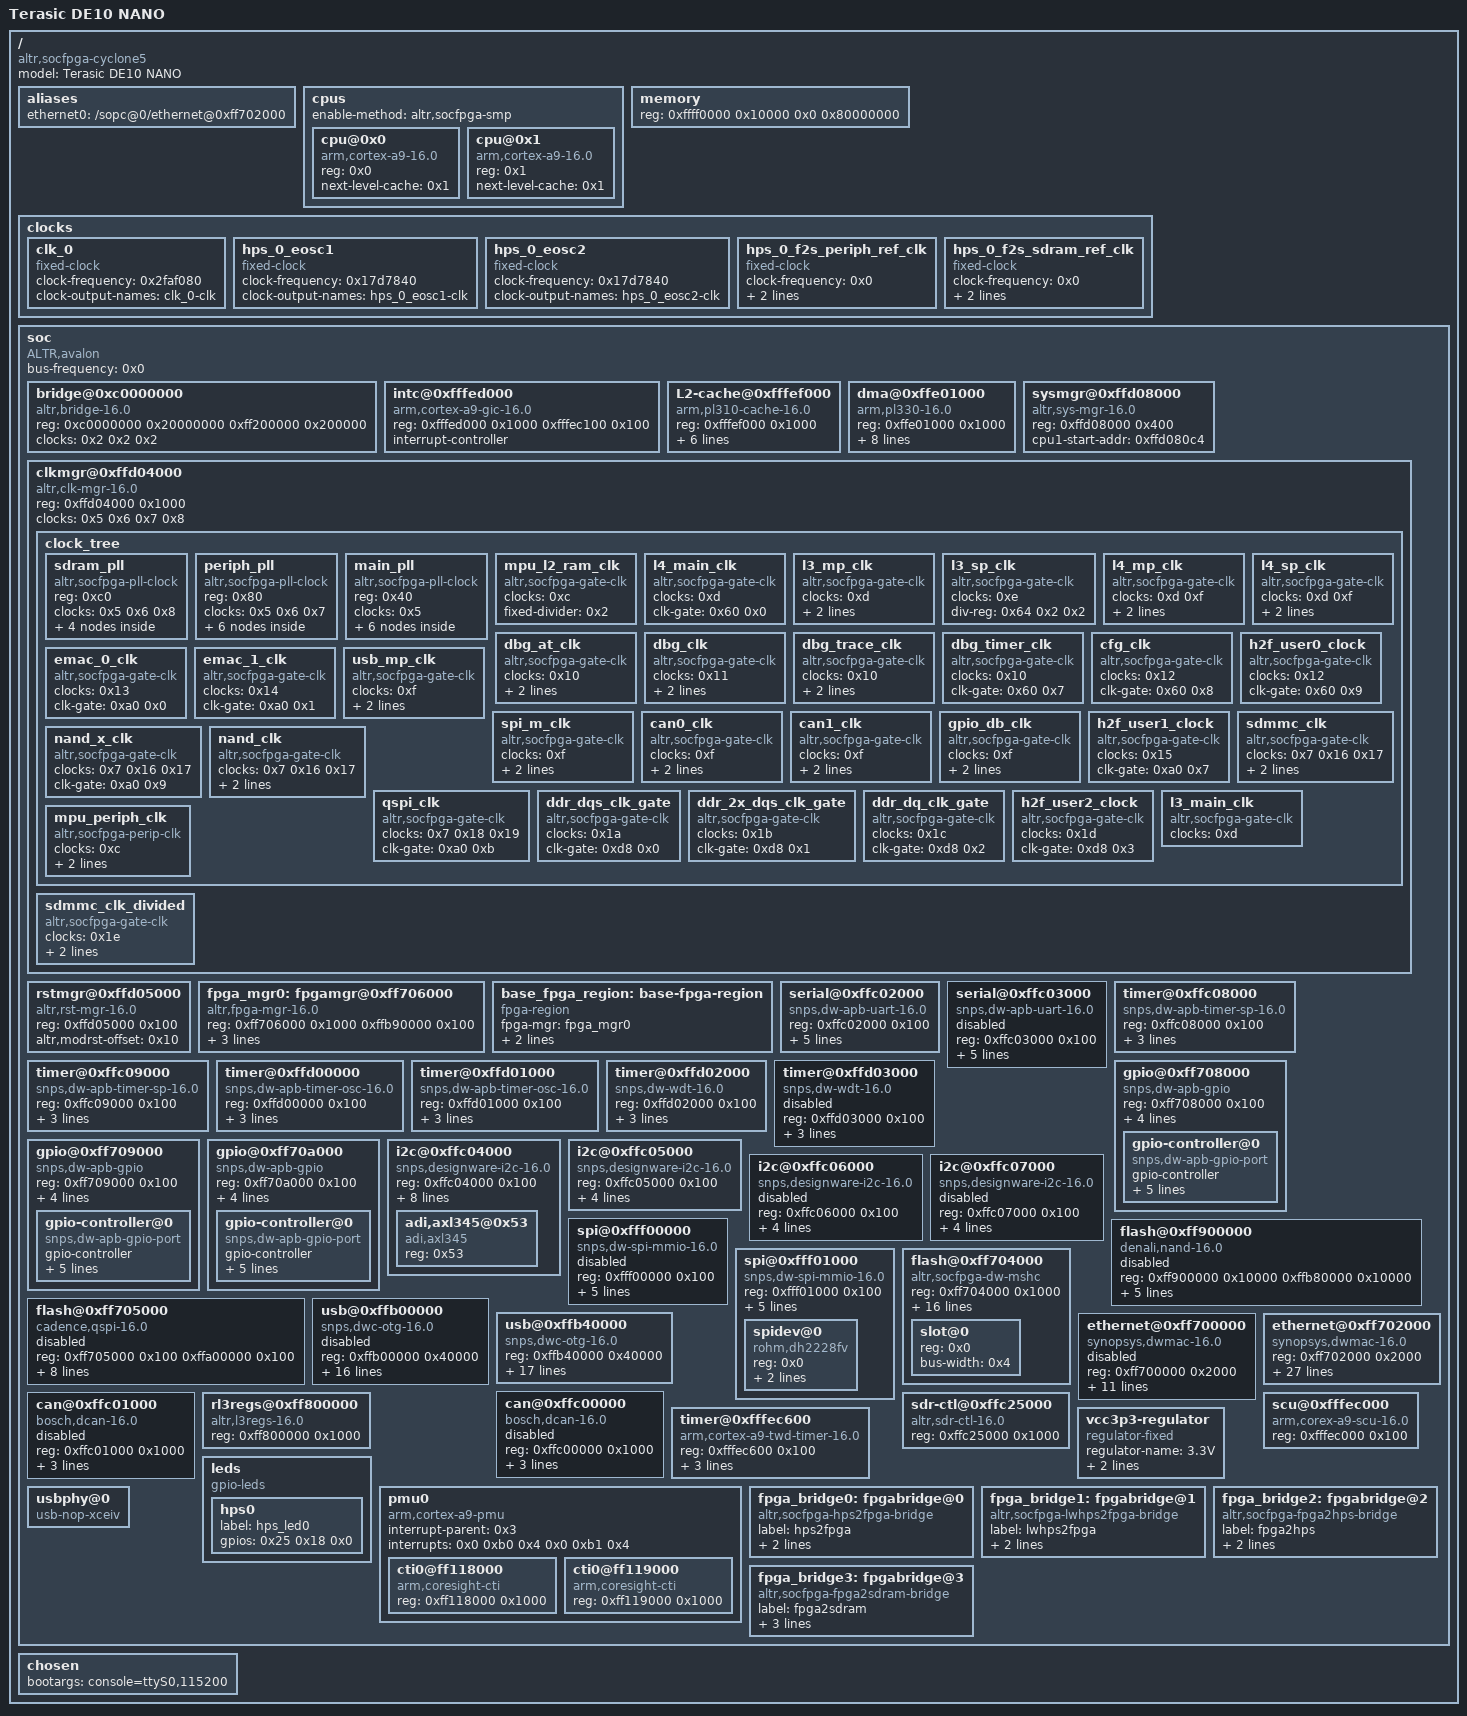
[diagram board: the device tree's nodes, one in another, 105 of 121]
/dts-v1/;

/ {
	model = "Terasic DE10 NANO";
	compatible = "altr,socfpga-cyclone5", "altr,socfpga";
	#address-cells = <0x1>;
	#size-cells = <0x1>;

	aliases {
		ethernet0 = "/sopc@0/ethernet@0xff702000";
	};

	cpus {
		#address-cells = <0x1>;
		#size-cells = <0x0>;
		enable-method = "altr,socfpga-smp";

		cpu@0x0 {
			device_type = "cpu";
			compatible = "arm,cortex-a9-16.0", "arm,cortex-a9";
			reg = <0x0>;
			next-level-cache = <0x1>;
		};

		cpu@0x1 {
			device_type = "cpu";
			compatible = "arm,cortex-a9-16.0", "arm,cortex-a9";
			reg = <0x1>;
			next-level-cache = <0x1>;
		};
	};

	memory {
		device_type = "memory";
		reg = <0xffff0000 0x10000 0x0 0x80000000>;
	};

	clocks {
		#address-cells = <0x1>;
		#size-cells = <0x1>;

		clk_0 {
			compatible = "fixed-clock";
			#clock-cells = <0x0>;
			clock-frequency = <0x2faf080>;
			clock-output-names = "clk_0-clk";
			linux,phandle = <0x2>;
			phandle = <0x2>;
		};

		hps_0_eosc1 {
			compatible = "fixed-clock";
			#clock-cells = <0x0>;
			clock-frequency = <0x17d7840>;
			clock-output-names = "hps_0_eosc1-clk";
			linux,phandle = <0x5>;
			phandle = <0x5>;
		};

		hps_0_eosc2 {
			compatible = "fixed-clock";
			#clock-cells = <0x0>;
			clock-frequency = <0x17d7840>;
			clock-output-names = "hps_0_eosc2-clk";
			linux,phandle = <0x6>;
			phandle = <0x6>;
		};

		hps_0_f2s_periph_ref_clk {
			compatible = "fixed-clock";
			#clock-cells = <0x0>;
			clock-frequency = <0x0>;
			clock-output-names = "hps_0_f2s_periph_ref_clk-clk";
			linux,phandle = <0x7>;
			phandle = <0x7>;
		};

		hps_0_f2s_sdram_ref_clk {
			compatible = "fixed-clock";
			#clock-cells = <0x0>;
			clock-frequency = <0x0>;
			clock-output-names = "hps_0_f2s_sdram_ref_clk-clk";
			linux,phandle = <0x8>;
			phandle = <0x8>;
		};
	};

	soc {
		device_type = "soc";
		ranges;
		#address-cells = <0x1>;
		#size-cells = <0x1>;
		compatible = "ALTR,avalon", "simple-bus";
		bus-frequency = <0x0>;

		bridge@0xc0000000 {
			compatible = "altr,bridge-16.0", "simple-bus";
			reg = <0xc0000000 0x20000000 0xff200000 0x200000>;
			reg-names = "axi_h2f", "axi_h2f_lw";
			clocks = <0x2 0x2 0x2>;
			clock-names = "h2f_axi_clock", "h2f_lw_axi_clock", "f2h_sdram0_clock";
			#address-cells = <0x2>;
			#size-cells = <0x1>;
		};

		intc@0xfffed000 {
			compatible = "arm,cortex-a9-gic-16.0", "arm,cortex-a9-gic";
			reg = <0xfffed000 0x1000 0xfffec100 0x100>;
			reg-names = "axi_slave0", "axi_slave1";
			interrupt-controller;
			#interrupt-cells = <0x3>;
			linux,phandle = <0x3>;
			phandle = <0x3>;
		};

		L2-cache@0xfffef000 {
			compatible = "arm,pl310-cache-16.0", "arm,pl310-cache";
			reg = <0xfffef000 0x1000>;
			interrupt-parent = <0x3>;
			interrupts = <0x0 0x26 0x4>;
			cache-level = <0x2>;
			cache-unified;
			arm,tag-latency = <0x1 0x1 0x1>;
			arm,data-latency = <0x2 0x1 0x1>;
			linux,phandle = <0x1>;
			phandle = <0x1>;
		};

		dma@0xffe01000 {
			compatible = "arm,pl330-16.0", "arm,pl330", "arm,primecell";
			reg = <0xffe01000 0x1000>;
			interrupt-parent = <0x3>;
			interrupts = <0x0 0x68 0x4>;
			clocks = <0x4>;
			#dma-cells = <0x1>;
			#dma-channels = <0x8>;
			#dma-requests = <0x20>;
			clock-names = "apb_pclk";
			copy-align = <0x3>;
			nr-irqs = <0x9>;
			nr-valid-peri = <0x9>;
		};

		sysmgr@0xffd08000 {
			compatible = "altr,sys-mgr-16.0", "altr,sys-mgr", "syscon";
			reg = <0xffd08000 0x400>;
			cpu1-start-addr = <0xffd080c4>;
			linux,phandle = <0x2a>;
			phandle = <0x2a>;
		};

		clkmgr@0xffd04000 {
			compatible = "altr,clk-mgr-16.0", "altr,clk-mgr";
			reg = <0xffd04000 0x1000>;
			clocks = <0x5 0x6 0x7 0x8>;
			clock-names = "eosc1", "eosc2", "f2s_periph_ref_clk", "f2s_sdram_ref_clk";

			clock_tree {
				#size-cells = <0x0>;
				#address-cells = <0x1>;

				sdram_pll {
					compatible = "altr,socfpga-pll-clock";
					reg = <0xc0>;
					clocks = <0x5 0x6 0x8>;
					clock-names = "hps_0_eosc1", "hps_0_eosc2", "hps_0_f2s_sdram_ref_clk";
					#clock-cells = <0x0>;
					#address-cells = <0x1>;
					#size-cells = <0x0>;
					linux,phandle = <0x9>;
					phandle = <0x9>;

					ddr_dqs_clk {
						compatible = "altr,socfpga-perip-clk";
						reg = <0xc8>;
						clocks = <0x9>;
						#clock-cells = <0x0>;
						linux,phandle = <0x1a>;
						phandle = <0x1a>;
					};

					ddr_2x_dqs_clk {
						compatible = "altr,socfpga-perip-clk";
						reg = <0xcc>;
						clocks = <0x9>;
						#clock-cells = <0x0>;
						linux,phandle = <0x1b>;
						phandle = <0x1b>;
					};

					ddr_dq_clk {
						compatible = "altr,socfpga-perip-clk";
						reg = <0xd0>;
						clocks = <0x9>;
						#clock-cells = <0x0>;
						linux,phandle = <0x1c>;
						phandle = <0x1c>;
					};

					s2f_usr2_clk {
						compatible = "altr,socfpga-perip-clk";
						reg = <0xd4>;
						clocks = <0x9>;
						#clock-cells = <0x0>;
						linux,phandle = <0x1d>;
						phandle = <0x1d>;
					};
				};

				periph_pll {
					compatible = "altr,socfpga-pll-clock";
					reg = <0x80>;
					clocks = <0x5 0x6 0x7>;
					clock-names = "hps_0_eosc1", "hps_0_eosc2", "hps_0_f2s_periph_ref_clk";
					#clock-cells = <0x0>;
					#address-cells = <0x1>;
					#size-cells = <0x0>;
					linux,phandle = <0xa>;
					phandle = <0xa>;

					per_nand_mmc_clk {
						compatible = "altr,socfpga-perip-clk";
						reg = <0x94>;
						clocks = <0xa>;
						#clock-cells = <0x0>;
						linux,phandle = <0x17>;
						phandle = <0x17>;
					};

					per_base_clk {
						compatible = "altr,socfpga-perip-clk";
						reg = <0x98>;
						clocks = <0xa>;
						#clock-cells = <0x0>;
						linux,phandle = <0xf>;
						phandle = <0xf>;
					};

					per_qspi_clk {
						compatible = "altr,socfpga-perip-clk";
						reg = <0x90>;
						clocks = <0xa>;
						#clock-cells = <0x0>;
						linux,phandle = <0x19>;
						phandle = <0x19>;
					};

					s2f_usr1_clk {
						compatible = "altr,socfpga-perip-clk";
						reg = <0x9c>;
						clocks = <0xa>;
						#clock-cells = <0x0>;
						linux,phandle = <0x15>;
						phandle = <0x15>;
					};

					emac0_clk {
						compatible = "altr,socfpga-perip-clk";
						reg = <0x88>;
						clocks = <0xa>;
						#clock-cells = <0x0>;
						linux,phandle = <0x13>;
						phandle = <0x13>;
					};

					emac1_clk {
						compatible = "altr,socfpga-perip-clk";
						reg = <0x8c>;
						clocks = <0xa>;
						#clock-cells = <0x0>;
						linux,phandle = <0x14>;
						phandle = <0x14>;
					};
				};

				main_pll {
					compatible = "altr,socfpga-pll-clock";
					reg = <0x40>;
					clocks = <0x5>;
					#clock-cells = <0x0>;
					#address-cells = <0x1>;
					#size-cells = <0x0>;
					linux,phandle = <0xb>;
					phandle = <0xb>;

					cfg_s2f_usr0_clk {
						compatible = "altr,socfpga-perip-clk";
						reg = <0x5c>;
						clocks = <0xb>;
						#clock-cells = <0x0>;
						linux,phandle = <0x12>;
						phandle = <0x12>;
					};

					main_qspi_clk {
						compatible = "altr,socfpga-perip-clk";
						reg = <0x54>;
						clocks = <0xb>;
						#clock-cells = <0x0>;
						linux,phandle = <0x18>;
						phandle = <0x18>;
					};

					dbg_base_clk {
						compatible = "altr,socfpga-perip-clk";
						reg = <0x50>;
						clocks = <0xb 0x5>;
						clock-names = "main_pll", "hps_0_eosc1";
						#clock-cells = <0x0>;
						div-reg = <0xe8 0x0 0x9>;
						linux,phandle = <0x10>;
						phandle = <0x10>;
					};

					mpuclk {
						compatible = "altr,socfpga-perip-clk";
						reg = <0x48>;
						clocks = <0xb>;
						#clock-cells = <0x0>;
						div-reg = <0xe0 0x0 0x9>;
						linux,phandle = <0xc>;
						phandle = <0xc>;
					};

					mainclk {
						compatible = "altr,socfpga-perip-clk";
						reg = <0x4c>;
						clocks = <0xb>;
						#clock-cells = <0x0>;
						div-reg = <0xe4 0x0 0x9>;
						linux,phandle = <0xd>;
						phandle = <0xd>;
					};

					main_nand_sdmmc_clk {
						compatible = "altr,socfpga-perip-clk";
						reg = <0x58>;
						clocks = <0xb>;
						#clock-cells = <0x0>;
						linux,phandle = <0x16>;
						phandle = <0x16>;
					};
				};

				mpu_l2_ram_clk {
					compatible = "altr,socfpga-gate-clk";
					clocks = <0xc>;
					#clock-cells = <0x0>;
					fixed-divider = <0x2>;
				};

				l4_main_clk {
					compatible = "altr,socfpga-gate-clk";
					clocks = <0xd>;
					#clock-cells = <0x0>;
					clk-gate = <0x60 0x0>;
					linux,phandle = <0x4>;
					phandle = <0x4>;
				};

				l3_mp_clk {
					compatible = "altr,socfpga-gate-clk";
					clocks = <0xd>;
					#clock-cells = <0x0>;
					clk-gate = <0x60 0x1>;
					div-reg = <0x64 0x0 0x2>;
					linux,phandle = <0xe>;
					phandle = <0xe>;
				};

				l3_sp_clk {
					compatible = "altr,socfpga-gate-clk";
					clocks = <0xe>;
					#clock-cells = <0x0>;
					div-reg = <0x64 0x2 0x2>;
				};

				l4_mp_clk {
					compatible = "altr,socfpga-gate-clk";
					clocks = <0xd 0xf>;
					clock-names = "mainclk", "per_base_clk";
					#clock-cells = <0x0>;
					clk-gate = <0x60 0x2>;
					div-reg = <0x64 0x4 0x3>;
					linux,phandle = <0x20>;
					phandle = <0x20>;
				};

				l4_sp_clk {
					compatible = "altr,socfpga-gate-clk";
					clocks = <0xd 0xf>;
					clock-names = "mainclk", "per_base_clk";
					#clock-cells = <0x0>;
					clk-gate = <0x60 0x3>;
					div-reg = <0x64 0x7 0x3>;
					linux,phandle = <0x1f>;
					phandle = <0x1f>;
				};

				dbg_at_clk {
					compatible = "altr,socfpga-gate-clk";
					clocks = <0x10>;
					#clock-cells = <0x0>;
					clk-gate = <0x60 0x4>;
					div-reg = <0x68 0x0 0x2>;
					linux,phandle = <0x11>;
					phandle = <0x11>;
				};

				dbg_clk {
					compatible = "altr,socfpga-gate-clk";
					clocks = <0x11>;
					#clock-cells = <0x0>;
					clk-gate = <0x60 0x5>;
					div-reg = <0x68 0x2 0x2>;
				};

				dbg_trace_clk {
					compatible = "altr,socfpga-gate-clk";
					clocks = <0x10>;
					#clock-cells = <0x0>;
					clk-gate = <0x60 0x6>;
					div-reg = <0x6c 0x0 0x3>;
				};

				dbg_timer_clk {
					compatible = "altr,socfpga-gate-clk";
					clocks = <0x10>;
					#clock-cells = <0x0>;
					clk-gate = <0x60 0x7>;
				};

				cfg_clk {
					compatible = "altr,socfpga-gate-clk";
					clocks = <0x12>;
					#clock-cells = <0x0>;
					clk-gate = <0x60 0x8>;
				};

				h2f_user0_clock {
					compatible = "altr,socfpga-gate-clk";
					clocks = <0x12>;
					#clock-cells = <0x0>;
					clk-gate = <0x60 0x9>;
				};

				emac_0_clk {
					compatible = "altr,socfpga-gate-clk";
					clocks = <0x13>;
					#clock-cells = <0x0>;
					clk-gate = <0xa0 0x0>;
				};

				emac_1_clk {
					compatible = "altr,socfpga-gate-clk";
					clocks = <0x14>;
					#clock-cells = <0x0>;
					clk-gate = <0xa0 0x1>;
				};

				usb_mp_clk {
					compatible = "altr,socfpga-gate-clk";
					clocks = <0xf>;
					#clock-cells = <0x0>;
					clk-gate = <0xa0 0x2>;
					div-reg = <0xa4 0x0 0x3>;
					linux,phandle = <0x27>;
					phandle = <0x27>;
				};

				spi_m_clk {
					compatible = "altr,socfpga-gate-clk";
					clocks = <0xf>;
					#clock-cells = <0x0>;
					clk-gate = <0xa0 0x3>;
					div-reg = <0xa4 0x3 0x3>;
					linux,phandle = <0x22>;
					phandle = <0x22>;
				};

				can0_clk {
					compatible = "altr,socfpga-gate-clk";
					clocks = <0xf>;
					#clock-cells = <0x0>;
					clk-gate = <0xa0 0x4>;
					div-reg = <0xa4 0x6 0x3>;
					linux,phandle = <0x2b>;
					phandle = <0x2b>;
				};

				can1_clk {
					compatible = "altr,socfpga-gate-clk";
					clocks = <0xf>;
					#clock-cells = <0x0>;
					clk-gate = <0xa0 0x5>;
					div-reg = <0xa4 0x9 0x3>;
					linux,phandle = <0x2c>;
					phandle = <0x2c>;
				};

				gpio_db_clk {
					compatible = "altr,socfpga-gate-clk";
					clocks = <0xf>;
					#clock-cells = <0x0>;
					clk-gate = <0xa0 0x6>;
					div-reg = <0xa8 0x0 0x18>;
				};

				h2f_user1_clock {
					compatible = "altr,socfpga-gate-clk";
					clocks = <0x15>;
					#clock-cells = <0x0>;
					clk-gate = <0xa0 0x7>;
				};

				sdmmc_clk {
					compatible = "altr,socfpga-gate-clk";
					clocks = <0x7 0x16 0x17>;
					clock-names = "hps_0_f2s_periph_ref_clk", "main_nand_sdmmc_clk", "per_nand_mmc_clk";
					#clock-cells = <0x0>;
					clk-gate = <0xa0 0x8>;
					clk-phase = <0x0 0x87>;
					linux,phandle = <0x1e>;
					phandle = <0x1e>;
				};

				nand_x_clk {
					compatible = "altr,socfpga-gate-clk";
					clocks = <0x7 0x16 0x17>;
					clock-names = "hps_0_f2s_periph_ref_clk", "main_nand_sdmmc_clk", "per_nand_mmc_clk";
					#clock-cells = <0x0>;
					clk-gate = <0xa0 0x9>;
				};

				nand_clk {
					compatible = "altr,socfpga-gate-clk";
					clocks = <0x7 0x16 0x17>;
					clock-names = "hps_0_f2s_periph_ref_clk", "main_nand_sdmmc_clk", "per_nand_mmc_clk";
					#clock-cells = <0x0>;
					clk-gate = <0xa0 0xa>;
					fixed-divider = <0x4>;
					linux,phandle = <0x21>;
					phandle = <0x21>;
				};

				qspi_clk {
					compatible = "altr,socfpga-gate-clk";
					clocks = <0x7 0x18 0x19>;
					clock-names = "hps_0_f2s_periph_ref_clk", "main_qspi_clk", "per_qspi_clk";
					#clock-cells = <0x0>;
					clk-gate = <0xa0 0xb>;
					linux,phandle = <0x23>;
					phandle = <0x23>;
				};

				ddr_dqs_clk_gate {
					compatible = "altr,socfpga-gate-clk";
					clocks = <0x1a>;
					#clock-cells = <0x0>;
					clk-gate = <0xd8 0x0>;
				};

				ddr_2x_dqs_clk_gate {
					compatible = "altr,socfpga-gate-clk";
					clocks = <0x1b>;
					#clock-cells = <0x0>;
					clk-gate = <0xd8 0x1>;
				};

				ddr_dq_clk_gate {
					compatible = "altr,socfpga-gate-clk";
					clocks = <0x1c>;
					#clock-cells = <0x0>;
					clk-gate = <0xd8 0x2>;
				};

				h2f_user2_clock {
					compatible = "altr,socfpga-gate-clk";
					clocks = <0x1d>;
					#clock-cells = <0x0>;
					clk-gate = <0xd8 0x3>;
				};

				l3_main_clk {
					compatible = "altr,socfpga-gate-clk";
					clocks = <0xd>;
					#clock-cells = <0x0>;
				};

				mpu_periph_clk {
					compatible = "altr,socfpga-perip-clk";
					clocks = <0xc>;
					#clock-cells = <0x0>;
					reg = <0x0>;
					fixed-divider = <0x4>;
					linux,phandle = <0x2d>;
					phandle = <0x2d>;
				};
			};

			sdmmc_clk_divided {
				#clock-cells = <0x0>;
				compatible = "altr,socfpga-gate-clk";
				clocks = <0x1e>;
				clk-gate = <0xa0 0x8>;
				fixed-divider = <0x4>;
				linux,phandle = <0x24>;
				phandle = <0x24>;
			};
		};

		rstmgr@0xffd05000 {
			compatible = "altr,rst-mgr-16.0", "altr,rst-mgr", "syscon";
			reg = <0xffd05000 0x100>;
			#reset-cells = <0x1>;
			altr,modrst-offset = <0x10>;
			linux,phandle = <0x29>;
			phandle = <0x29>;
		};

		fpga_mgr0: fpgamgr@0xff706000 {
			compatible = "altr,fpga-mgr-16.0", "altr,fpga-mgr";
			reg = <0xff706000 0x1000 0xffb90000 0x100>;
			reg-names = "axi_slave0", "axi_slave1";
			interrupt-parent = <0x3>;
			interrupts = <0x0 0xaf 0x4>;
			transport = "mmio";
		};

    base_fpga_region: base-fpga-region {
      compatible = "fpga-region";
      fpga-mgr = <&fpga_mgr0>;
      fpga-bridges = <&fpga_bridge0>, <&fpga_bridge1>,
                     <&fpga_bridge2>, <&fpga_bridge3>;

      #address-cells = <0x2>;
      #size-cells = <0x1>;
      ranges = <0x00000000 0x00000000 0xc0000000 0x20000000>,
               <0x00000001 0x00000000 0xff200000 0x00200000>;
    };
    
		serial@0xffc02000 {
			compatible = "snps,dw-apb-uart-16.0", "snps,dw-apb-uart";
			reg = <0xffc02000 0x100>;
			interrupt-parent = <0x3>;
			interrupts = <0x0 0xa2 0x4>;
			clocks = <0x1f>;
			reg-io-width = <0x4>;
			reg-shift = <0x2>;
			status = "okay";
		};

		serial@0xffc03000 {
			compatible = "snps,dw-apb-uart-16.0", "snps,dw-apb-uart";
			reg = <0xffc03000 0x100>;
			interrupt-parent = <0x3>;
			interrupts = <0x0 0xa3 0x4>;
			clocks = <0x1f>;
			reg-io-width = <0x4>;
			reg-shift = <0x2>;
			status = "disabled";
		};

		timer@0xffc08000 {
			compatible = "snps,dw-apb-timer-sp-16.0", "snps,dw-apb-timer-sp";
			reg = <0xffc08000 0x100>;
			interrupt-parent = <0x3>;
			interrupts = <0x0 0xa7 0x4>;
			clocks = <0x1f>;
			clock-names = "timer";
		};

		timer@0xffc09000 {
			compatible = "snps,dw-apb-timer-sp-16.0", "snps,dw-apb-timer-sp";
			reg = <0xffc09000 0x100>;
			interrupt-parent = <0x3>;
			interrupts = <0x0 0xa8 0x4>;
			clocks = <0x1f>;
			clock-names = "timer";
		};

		timer@0xffd00000 {
			compatible = "snps,dw-apb-timer-osc-16.0", "snps,dw-apb-timer-osc";
			reg = <0xffd00000 0x100>;
			interrupt-parent = <0x3>;
			interrupts = <0x0 0xa9 0x4>;
			clocks = <0x5>;
			clock-names = "timer";
		};

		timer@0xffd01000 {
			compatible = "snps,dw-apb-timer-osc-16.0", "snps,dw-apb-timer-osc";
			reg = <0xffd01000 0x100>;
			interrupt-parent = <0x3>;
			interrupts = <0x0 0xaa 0x4>;
			clocks = <0x5>;
			clock-names = "timer";
		};

		timer@0xffd02000 {
			compatible = "snps,dw-wdt-16.0", "snps,dw-wdt";
			reg = <0xffd02000 0x100>;
			interrupt-parent = <0x3>;
			interrupts = <0x0 0xab 0x4>;
			clocks = <0x5>;
			clock-names = "timer";
		};

		timer@0xffd03000 {
			compatible = "snps,dw-wdt-16.0", "snps,dw-wdt";
			reg = <0xffd03000 0x100>;
			interrupt-parent = <0x3>;
			interrupts = <0x0 0xac 0x4>;
			clocks = <0xf>;
			clock-names = "timer";
			status = "disabled";
		};

		gpio@0xff708000 {
			compatible = "snps,dw-apb-gpio", "snps,dw-gpio-16.0", "snps,dw-gpio";
			reg = <0xff708000 0x100>;
			interrupt-parent = <0x3>;
			interrupts = <0x0 0xa4 0x4>;
			clocks = <0x20>;
			#gpio-cells = <0x2>;
			gpio-controller;
			#address-cells = <0x1>;
			#size-cells = <0x0>;

			gpio-controller@0 {
				compatible = "snps,dw-apb-gpio-port";
				gpio-controller;
				#gpio-cells = <0x2>;
				snps,nr-gpios = <0x1d>;
				reg = <0x0>;
				interrupt-controller;
				#interrupt-cells = <0x2>;
				interrupts = <0x0 0xa4 0x4>;
				interrupt-parent = <0x3>;
			};
		};

		gpio@0xff709000 {
			compatible = "snps,dw-apb-gpio", "snps,dw-gpio-16.0", "snps,dw-gpio";
			reg = <0xff709000 0x100>;
			interrupt-parent = <0x3>;
			interrupts = <0x0 0xa5 0x4>;
			clocks = <0x20>;
			#gpio-cells = <0x2>;
			gpio-controller;
			#address-cells = <0x1>;
			#size-cells = <0x0>;

			gpio-controller@0 {
				compatible = "snps,dw-apb-gpio-port";
				gpio-controller;
				#gpio-cells = <0x2>;
				snps,nr-gpios = <0x1d>;
				reg = <0x0>;
				interrupt-controller;
				#interrupt-cells = <0x2>;
				interrupts = <0x0 0xa5 0x4>;
				interrupt-parent = <0x3>;
				linux,phandle = <0x25>;
				phandle = <0x25>;
			};
		};

		gpio@0xff70a000 {
			compatible = "snps,dw-apb-gpio", "snps,dw-gpio-16.0", "snps,dw-gpio";
			reg = <0xff70a000 0x100>;
			interrupt-parent = <0x3>;
			interrupts = <0x0 0xa6 0x4>;
			clocks = <0x20>;
			#gpio-cells = <0x2>;
			gpio-controller;
			#address-cells = <0x1>;
			#size-cells = <0x0>;

			gpio-controller@0 {
				compatible = "snps,dw-apb-gpio-port";
				gpio-controller;
				#gpio-cells = <0x2>;
				snps,nr-gpios = <0x1b>;
				reg = <0x0>;
				interrupt-controller;
				#interrupt-cells = <0x2>;
				interrupts = <0x0 0xa6 0x4>;
				interrupt-parent = <0x3>;
			};
		};

		i2c@0xffc04000 {
			compatible = "snps,designware-i2c-16.0", "snps,designware-i2c";
			reg = <0xffc04000 0x100>;
			interrupt-parent = <0x3>;
			interrupts = <0x0 0x9e 0x4>;
			clocks = <0x1f>;
			emptyfifo_hold_master = <0x1>;
			status = "okay";
			#address-cells = <0x1>;
			#size-cells = <0x0>;
			speed-mode = <0x0>;
			clock-frequency = <0x186a0>;
			i2c-sda-falling-time-ns = <0x1388>;
			i2c-scl-falling-time-ns = <0x1388>;

			adi,axl345@0x53 {
				compatible = "adi,axl345";
				reg = <0x53>;
			};
		};

		i2c@0xffc05000 {
			compatible = "snps,designware-i2c-16.0", "snps,designware-i2c";
			reg = <0xffc05000 0x100>;
			interrupt-parent = <0x3>;
			interrupts = <0x0 0x9f 0x4>;
			clocks = <0x1f>;
			emptyfifo_hold_master = <0x1>;
			status = "okay";
		};

		i2c@0xffc06000 {
			compatible = "snps,designware-i2c-16.0", "snps,designware-i2c";
			reg = <0xffc06000 0x100>;
			interrupt-parent = <0x3>;
			interrupts = <0x0 0xa0 0x4>;
			clocks = <0x1f>;
			emptyfifo_hold_master = <0x1>;
			status = "disabled";
		};

		i2c@0xffc07000 {
			compatible = "snps,designware-i2c-16.0", "snps,designware-i2c";
			reg = <0xffc07000 0x100>;
			interrupt-parent = <0x3>;
			interrupts = <0x0 0xa1 0x4>;
			clocks = <0x1f>;
			emptyfifo_hold_master = <0x1>;
			status = "disabled";
		};

		flash@0xff900000 {
			compatible = "denali,nand-16.0", "denali,denali-nand-dt";
			reg = <0xff900000 0x10000 0xffb80000 0x10000>;
			reg-names = "nand_data", "denali_reg";
			interrupt-parent = <0x3>;
			interrupts = <0x0 0x90 0x4>;
			clocks = <0x21>;
			#address-cells = <0x1>;
			#size-cells = <0x1>;
			status = "disabled";
			bank-width = <0x2>;
			device-width = <0x1>;
		};

		spi@0xfff00000 {
			compatible = "snps,dw-spi-mmio-16.0", "snps,dw-spi-mmio", "snps,dw-apb-ssi";
			reg = <0xfff00000 0x100>;
			interrupt-parent = <0x3>;
			interrupts = <0x0 0x9a 0x4>;
			clocks = <0x22>;
			#address-cells = <0x1>;
			#size-cells = <0x0>;
			bus-num = <0x0>;
			num-chipselect = <0x4>;
			status = "disabled";
		};

		spi@0xfff01000 {
			compatible = "snps,dw-spi-mmio-16.0", "snps,dw-spi-mmio", "snps,dw-apb-ssi";
			reg = <0xfff01000 0x100>;
			interrupt-parent = <0x3>;
			interrupts = <0x0 0x9b 0x4>;
			clocks = <0x22>;
			#address-cells = <0x1>;
			#size-cells = <0x0>;
			bus-num = <0x0>;
			num-chipselect = <0x4>;
			status = "okay";

			spidev@0 {
				compatible = "rohm,dh2228fv";
				reg = <0x0>;
				spi-max-frequency = <0x5f5e100>;
				enable-dma = <0x1>;
			};
		};

		flash@0xff705000 {
			compatible = "cadence,qspi-16.0", "cadence,qspi", "cdns,qspi-nor";
			reg = <0xff705000 0x100 0xffa00000 0x100>;
			reg-names = "axi_slave0", "axi_slave1";
			interrupt-parent = <0x3>;
			interrupts = <0x0 0x97 0x4>;
			clocks = <0x23>;
			bus-num = <0x2>;
			fifo-depth = <0x80>;
			num-chipselect = <0x4>;
			status = "disabled";
			bank-width = <0x2>;
			device-width = <0x1>;
		};

		flash@0xff704000 {
			compatible = "altr,socfpga-dw-mshc";
			reg = <0xff704000 0x1000>;
			interrupt-parent = <0x3>;
			interrupts = <0x0 0x8b 0x4>;
			clocks = <0x20 0x24>;
			clock-names = "biu", "ciu";
			fifo-depth = <0x400>;
			num-slots = <0x1>;
			status = "okay";
			#address-cells = <0x1>;
			#size-cells = <0x0>;
			broken-cd;
			cap-mmc-highspeed;
			cap-sd-highspeed;
			bus-width = <0x4>;
			altr,dw-mshc-ciu-div = <0x3>;
			altr,dw-mshc-sdr-timing = <0x0 0x3>;
			supports-highspeed;
			cd = <0x25 0x12 0x0>;
			cd-gpios = <0x25 0x12 0x0>;
			vmmc-supply = <0x26>;
			vqmmc-supply = <0x26>;

			slot@0 {
				reg = <0x0>;
				bus-width = <0x4>;
			};
		};

		usb@0xffb00000 {
			compatible = "snps,dwc-otg-16.0", "snps,dwc-otg", "snps,dwc2";
			reg = <0xffb00000 0x40000>;
			interrupt-parent = <0x3>;
			interrupts = <0x0 0x7d 0x4>;
			clocks = <0x27>;
			clock-names = "otg";
			dev-nperio-tx-fifo-size = <0x1000>;
			dev-perio-tx-fifo-size = "<512 512 512 512 512 512 512 512 512 512 512 512 512 512 512>";
			dev-rx-fifo-size = <0x200>;
			dev-tx-fifo-size = "<512 512 512 512 512 512 512 512 512 512 512 512 512 512 512>";
			dma-mask = <0xfffffff>;
			enable-dynamic-fifo = <0x1>;
			host-nperio-tx-fifo-size = <0xa00>;
			host-perio-tx-fifo-size = <0xa00>;
			host-rx-fifo-size = <0xa00>;
			phy-names = "usb2-phy";
			status = "disabled";
			ulpi-ddr = <0x0>;
			voltage-switch = <0x0>;
		};

		usb@0xffb40000 {
			compatible = "snps,dwc-otg-16.0", "snps,dwc-otg", "snps,dwc2";
			reg = <0xffb40000 0x40000>;
			interrupt-parent = <0x3>;
			interrupts = <0x0 0x80 0x4>;
			clocks = <0x27>;
			clock-names = "otg";
			dev-nperio-tx-fifo-size = <0x1000>;
			dev-perio-tx-fifo-size = "<512 512 512 512 512 512 512 512 512 512 512 512 512 512 512>";
			dev-rx-fifo-size = <0x200>;
			dev-tx-fifo-size = "<512 512 512 512 512 512 512 512 512 512 512 512 512 512 512>";
			dma-mask = <0xfffffff>;
			enable-dynamic-fifo = <0x1>;
			host-nperio-tx-fifo-size = <0xa00>;
			host-perio-tx-fifo-size = <0xa00>;
			host-rx-fifo-size = <0xa00>;
			phy-names = "usb2-phy";
			status = "okay";
			ulpi-ddr = <0x0>;
			voltage-switch = <0x0>;
			phys = <0x28>;
		};

		ethernet@0xff700000 {
			compatible = "synopsys,dwmac-16.0", "altr,socfpga-stmmac", "snps,dwmac-3.70a", "snps,dwmac";
			reg = <0xff700000 0x2000>;
			interrupt-parent = <0x3>;
			interrupts = <0x0 0x73 0x4>;
			clocks = <0x13>;
			clock-names = "stmmaceth";
			interrupt-names = "macirq";
			rx-fifo-depth = <0x1000>;
			snps,multicast-filter-bins = <0x100>;
			snps,perfect-filter-entries = <0x80>;
			status = "disabled";
			tx-fifo-depth = <0x1000>;
			address-bits = <0x30>;
			max-frame-size = <0x5ee>;
			local-mac-address = [00 00 00 00 00 00];
			reset-names = "stmmaceth";
			resets = <0x29 0x20>;
		};

		ethernet@0xff702000 {
			compatible = "synopsys,dwmac-16.0", "altr,socfpga-stmmac", "snps,dwmac-3.70a", "snps,dwmac";
			reg = <0xff702000 0x2000>;
			interrupt-parent = <0x3>;
			interrupts = <0x0 0x78 0x4>;
			clocks = <0x14>;
			clock-names = "stmmaceth";
			interrupt-names = "macirq";
			rx-fifo-depth = <0x1000>;
			snps,multicast-filter-bins = <0x100>;
			snps,perfect-filter-entries = <0x80>;
			status = "okay";
			tx-fifo-depth = <0x1000>;
			address-bits = <0x30>;
			max-frame-size = <0xed8>;
			local-mac-address = [00 00 00 00 00 00];
			phy-mode = "rgmii";
			snps,phy-addr = <0xffffffff>;
			phy-addr = <0xffffffff>;
			txc-skew-ps = <0xbb8>;
			rxc-skew-ps = <0xbb8>;
			txen-skew-ps = <0x0>;
			rxdv-skew-ps = <0x0>;
			rxd0-skew-ps = <0x0>;
			rxd1-skew-ps = <0x0>;
			rxd2-skew-ps = <0x0>;
			rxd3-skew-ps = <0x0>;
			txd0-skew-ps = <0x0>;
			txd1-skew-ps = <0x0>;
			txd2-skew-ps = <0x0>;
			txd3-skew-ps = <0x0>;
			altr,sysmgr-syscon = <0x2a 0x60 0x2>;
			reset-names = "stmmaceth";
			resets = <0x29 0x21>;
		};

		can@0xffc00000 {
			compatible = "bosch,dcan-16.0", "bosch,d_can";
			reg = <0xffc00000 0x1000>;
			interrupt-parent = <0x3>;
			interrupts = <0x0 0x83 0x4 0x0 0x84 0x4>;
			interrupt-names = "interrupt_sender0", "interrupt_sender1";
			clocks = <0x2b>;
			status = "disabled";
		};

		can@0xffc01000 {
			compatible = "bosch,dcan-16.0", "bosch,d_can";
			reg = <0xffc01000 0x1000>;
			interrupt-parent = <0x3>;
			interrupts = <0x0 0x87 0x4 0x0 0x88 0x4>;
			interrupt-names = "interrupt_sender0", "interrupt_sender1";
			clocks = <0x2c>;
			status = "disabled";
		};

		rl3regs@0xff800000 {
			compatible = "altr,l3regs-16.0", "altr,l3regs", "syscon";
			reg = <0xff800000 0x1000>;
		};

		sdr-ctl@0xffc25000 {
			compatible = "altr,sdr-ctl-16.0", "altr,sdr-ctl", "syscon";
			reg = <0xffc25000 0x1000>;
		};

		timer@0xfffec600 {
			compatible = "arm,cortex-a9-twd-timer-16.0", "arm,cortex-a9-twd-timer";
			reg = <0xfffec600 0x100>;
			interrupt-parent = <0x3>;
			interrupts = <0x1 0xd 0xf04>;
			clocks = <0x2d>;
		};

		scu@0xfffec000 {
			compatible = "arm,corex-a9-scu-16.0", "arm,cortex-a9-scu";
			reg = <0xfffec000 0x100>;
		};

		vcc3p3-regulator {
			compatible = "regulator-fixed";
			regulator-name = "3.3V";
			regulator-min-microvolt = <0x325aa0>;
			regulator-max-microvolt = <0x325aa0>;
			linux,phandle = <0x26>;
			phandle = <0x26>;
		};

		leds {
			compatible = "gpio-leds";

			hps0 {
				label = "hps_led0";
				gpios = <0x25 0x18 0x0>;
			};
		};

		pmu0 {
			#address-cells = <0x1>;
			#size-cells = <0x1>;
			compatible = "arm,cortex-a9-pmu";
			interrupt-parent = <0x3>;
			interrupts = <0x0 0xb0 0x4 0x0 0xb1 0x4>;
			ranges;

			cti0@ff118000 {
				compatible = "arm,coresight-cti";
				reg = <0xff118000 0x1000>;
			};

			cti0@ff119000 {
				compatible = "arm,coresight-cti";
				reg = <0xff119000 0x1000>;
			};
		};

		fpga_bridge0: fpgabridge@0 {
			compatible = "altr,socfpga-hps2fpga-bridge";
			label = "hps2fpga";
			reset-names = "hps2fpga";
			clocks = <0x4>;
			resets = <0x29 0x60>;
		};

		fpga_bridge1: fpgabridge@1 {
			compatible = "altr,socfpga-lwhps2fpga-bridge";
			label = "lwhps2fpga";
			reset-names = "lwhps2fpga";
			clocks = <0x4>;
			resets = <0x29 0x61>;
		};

		fpga_bridge2: fpgabridge@2 {
			compatible = "altr,socfpga-fpga2hps-bridge";
			label = "fpga2hps";
			reset-names = "fpga2hps";
			clocks = <0x4>;
			resets = <0x29 0x62>;
		};

		fpga_bridge3: fpgabridge@3 {
			compatible = "altr,socfpga-fpga2sdram-bridge";
			label = "fpga2sdram";
			read-ports-mask = <0xf>;
			write-ports-mask = <0xf>;
			cmd-ports-mask = <0x1>;
		};

		usbphy@0 {
			#phy-cells = <0x0>;
			compatible = "usb-nop-xceiv";
			status = "okay";
			linux,phandle = <0x28>;
			phandle = <0x28>;
		};
	};

	chosen {
		bootargs = "console=ttyS0,115200";
	};
};
